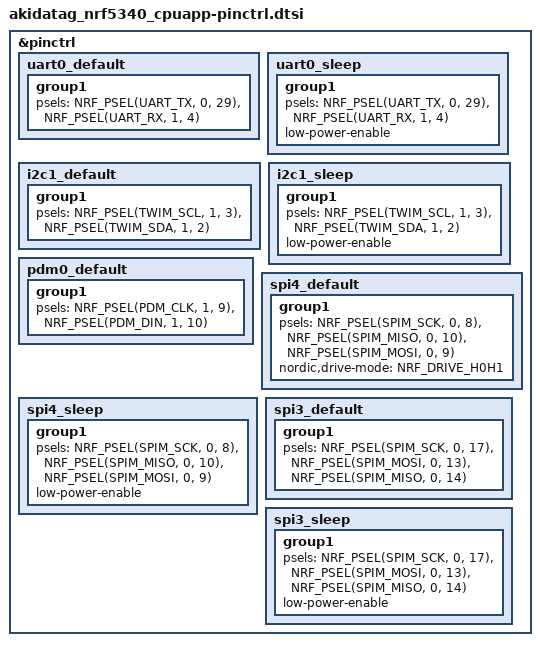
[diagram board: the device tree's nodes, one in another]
&pinctrl {
	uart0_default: uart0_default {
		group1 {
			psels = <NRF_PSEL(UART_TX, 0, 29)>,
				<NRF_PSEL(UART_RX, 1, 4)>;
		};
	};

	uart0_sleep: uart0_sleep {
		group1 {
			psels = <NRF_PSEL(UART_TX, 0, 29)>,
				<NRF_PSEL(UART_RX, 1, 4)>;
			low-power-enable;
		};
	};

	i2c1_default: i2c1_default {
		group1 {
			psels = <NRF_PSEL(TWIM_SCL, 1, 3)>,
				<NRF_PSEL(TWIM_SDA, 1, 2)>;
		};
	};

	i2c1_sleep: i2c1_sleep {
		group1 {
			psels = <NRF_PSEL(TWIM_SCL, 1, 3)>,
				<NRF_PSEL(TWIM_SDA, 1, 2)>;
			low-power-enable;
		};
	};

	pdm0_default: pdm0_default {
		group1 {
			psels = <NRF_PSEL(PDM_CLK, 1, 9)>,
				<NRF_PSEL(PDM_DIN, 1, 10)>;
		};
	};

	/* P0.08 to P0.10 are the SPIM4 high-speed pins. High drive keeps the SCK
	 * and MOSI edges clean at 16 and 32 MHz.
	 */
	spi4_default: spi4_default {
		group1 {
			psels = <NRF_PSEL(SPIM_SCK, 0, 8)>,
				<NRF_PSEL(SPIM_MISO, 0, 10)>,
				<NRF_PSEL(SPIM_MOSI, 0, 9)>;
			nordic,drive-mode = <NRF_DRIVE_H0H1>;
		};
	};

	spi4_sleep: spi4_sleep {
		group1 {
			psels = <NRF_PSEL(SPIM_SCK, 0, 8)>,
				<NRF_PSEL(SPIM_MISO, 0, 10)>,
				<NRF_PSEL(SPIM_MOSI, 0, 9)>;
			low-power-enable;
		};
	};

	spi3_default: spi3_default {
		group1 {
			psels = <NRF_PSEL(SPIM_SCK, 0, 17)>,
				<NRF_PSEL(SPIM_MOSI, 0, 13)>,
				<NRF_PSEL(SPIM_MISO, 0, 14)>;
		};
	};

	spi3_sleep: spi3_sleep {
		group1 {
			psels = <NRF_PSEL(SPIM_SCK, 0, 17)>,
				<NRF_PSEL(SPIM_MOSI, 0, 13)>,
				<NRF_PSEL(SPIM_MISO, 0, 14)>;
			low-power-enable;
		};
	};
};
